# RS1xxxx register map
Vendor: Silicon Lab Inc.; Series: ARMCM4; File version: 1.2
CPU: CM4 r1p0, little endian, MPU, FPU, 6 interrupt priority bits
Registers are 32-bit, read-write, reset 0x0 unless marked. A register's access mark holds for its fields unless they carry their own. Offsets are from the block's base; [hi:lo] are bit positions.

## Sleep_Clock_Calibrator — In this the time periods of 32KHz RC clock, 32KHz RO clock and 32KHz XTAL clock can be calibrated
Base 0x24048200
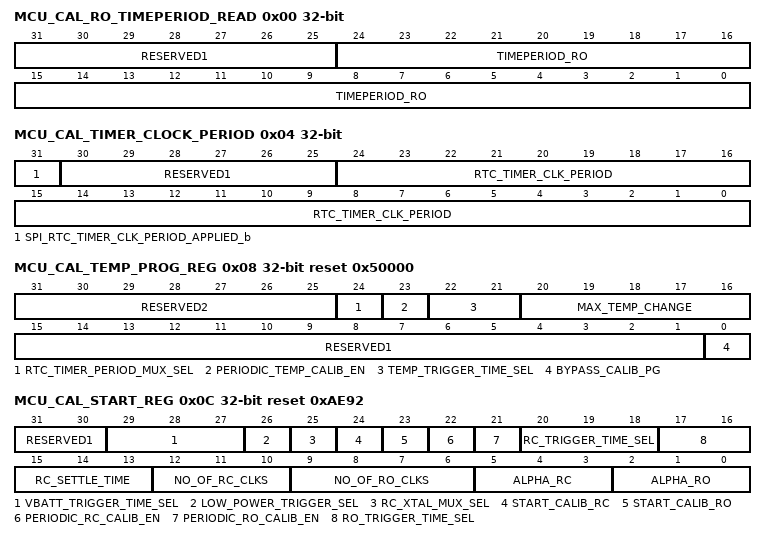
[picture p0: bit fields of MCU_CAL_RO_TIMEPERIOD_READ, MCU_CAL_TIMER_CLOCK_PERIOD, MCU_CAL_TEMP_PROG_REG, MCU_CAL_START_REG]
0x00 MCU_CAL_RO_TIMEPERIOD_READ — RO timeperiod read register
  [31:25] RESERVED1 ro — reser
  [24:0] TIMEPERIOD_RO ro — Calibrated RO timeperiod
0x04 MCU_CAL_TIMER_CLOCK_PERIOD — MCU calender timer clock period register
  [31] SPI_RTC_TIMER_CLK_PERIOD_APPLIED_b ro — Indicated SOC programmed rtc_timer clock period is applied at KHz clock domain
  [30:25] RESERVED1 ro — reser
  [24:0] RTC_TIMER_CLK_PERIOD — RTC timer clock period programmed by SOC
0x08 MCU_CAL_TEMP_PROG_REG reset 0x50000 — temprature program register
  [31:25] RESERVED2 ro — reser
  [24] RTC_TIMER_PERIOD_MUX_SEL — rtc timer period mux select
  [23] PERIODIC_TEMP_CALIB_EN — Enable periodic checking of temperature
  [22:21] TEMP_TRIGGER_TIME_SEL — temperature trigger time select
  [20:16] MAX_TEMP_CHANGE — maximum temperature change after which rc calibration must be trigger
  [15:1] RESERVED1 ro — reser
  [0] BYPASS_CALIB_PG — To bypass power gating and keep all the blocks always on
0x0C MCU_CAL_START_REG reset 0xAE92 — mcu cal start register
  [31:30] RESERVED1 ro — reser
  [29:27] VBATT_TRIGGER_TIME_SEL — trigger to ipmu block for checking vbatt status periodicaly
  [26] LOW_POWER_TRIGGER_SEL — power trigger select
  [25] RC_XTAL_MUX_SEL — xtal mux select
  [24] START_CALIB_RC wo — to initiate RC calibration
  [23] START_CALIB_RO wo — to initiate RO calibration
  [22] PERIODIC_RC_CALIB_EN — periodically calibrate RC timeperiod based rc trigger time sel
  [21] PERIODIC_RO_CALIB_EN — periodically calibrate RO timeperiod based ro trigger time sel
  [20:18] RC_TRIGGER_TIME_SEL — rc trigger time select
  [17:16] RO_TRIGGER_TIME_SEL — ro trigger time select
  [15:13] RC_SETTLE_TIME — no of clocks of RO for the RC clk to settle when enabled
  [12:10] NO_OF_RC_CLKS — 2^no_of_rc_clocks = no of rc clocks used in calibration
  [9:6] NO_OF_RO_CLKS — 2^no_of_ro_clks no of clocks of ro clock counts for no of rc clocks in that time to measure timeperiod
  [5:3] ALPHA_RC — alpha = 1/2^alpha_rc , averaging factor of RC timeperiod T = alpha(t_inst) + (1- alpha )t_prev
  [2:0] ALPHA_RO — alpha = 1/2^alpha_ro , averaging factor of RO timeperiod T = alpha(t_inst) + (1- alpha )t_prev
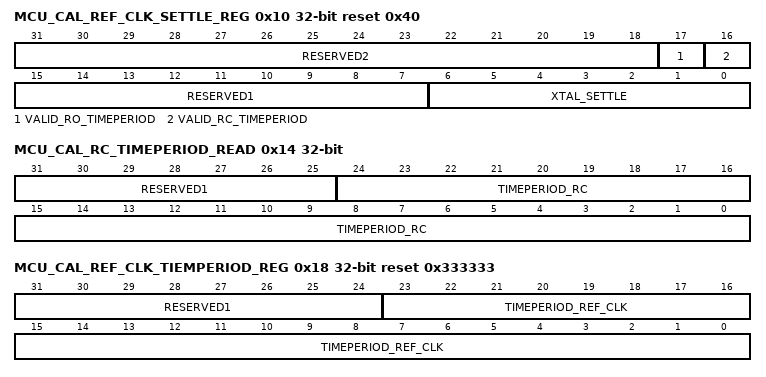
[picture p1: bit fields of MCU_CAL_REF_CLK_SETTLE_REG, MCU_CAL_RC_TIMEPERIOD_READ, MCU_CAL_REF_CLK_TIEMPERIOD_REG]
0x10 MCU_CAL_REF_CLK_SETTLE_REG reset 0x40 — reference clock settle register
  [31:18] RESERVED2 ro — reser
  [17] VALID_RO_TIMEPERIOD ro — Valid signal for reading RO timeperiod
  [16] VALID_RC_TIMEPERIOD ro — Valid signal for reading RC timeperiod calibrated
  [15:7] RESERVED1 ro — reser
  [6:0] XTAL_SETTLE — no of 32khz clocks for xtal 40mhz clk to settle
0x14 MCU_CAL_RC_TIMEPERIOD_READ — rc timeperiod read register
  [31:25] RESERVED1 ro — reser
  [24:0] TIMEPERIOD_RC ro — Calibrated RC timeperiod
0x18 MCU_CAL_REF_CLK_TIEMPERIOD_REG reset 0x333333 — reference clock timeperiod register
  [31:24] RESERVED1 ro — reser
  [23:0] TIMEPERIOD_REF_CLK — timeperiod of reference clk with each bit corresponding to granularity of 2^27 = 1us

## WDT — A dedicated window watch dog timer for MCU applications
Base 0x24048300
0x00 MCU_WWD_INTERRUPT_TIMER — WATCHDOG interrupt timer register
  [7:0] WWD_INTERRUPT_TIMER — Watchdog Timer programming values
0x04 MCU_WWD_SYSTEM_RESET_TIMER — MCU watchdog system reset register
  [7:0] WWD_SYSTEM_RESET_TIMER — Watch dog soc reset delay timer programming values
0x08 MCU_WWD_WINDOW_TIMER — watchdog window timer register
  [3:0] WINDOW_TIMER — watchdog window timer
0x0C MCU_WWD_PROC_STUCK_EN — watchdog arm stuck enable register
  [16] PROCESSOR_STUCK_RESET_EN wo — Enable to reset M4 core on seeing LOCKUP signal
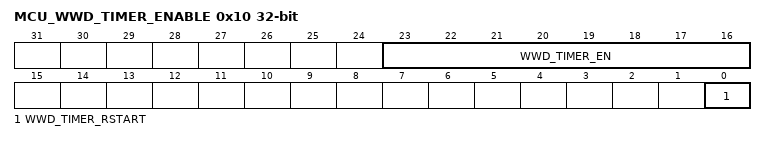
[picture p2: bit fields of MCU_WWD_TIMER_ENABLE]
0x10 MCU_WWD_TIMER_ENABLE — WDT Enable register
  [23:16] WWD_TIMER_EN wo — OXAA Enables WDT, OXF0 Disables WDT
  [0] WWD_TIMER_RSTART wo — Writing 1 restarts WDT ,writing 0 no effect
0x18 MCU_WWD_KEY_ENABLE wo reset 0x877F38E9 — watchdog key enable register
  [31:0] WWD_KEY_ENABLE — Writing 0x877F38E9 enables Read access,0x0AAAAAAA disables it of WDT TIMERS
